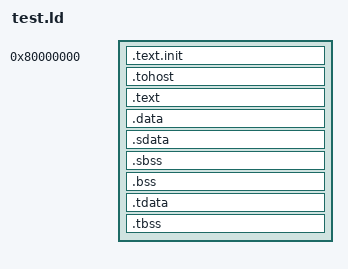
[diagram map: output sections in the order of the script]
/*======================================================================*/
/* Proxy kernel linker script                                           */
/*======================================================================*/
/* This is the linker script used to build the baremetal benchmarks     *
 * Compared to the original linker script shipped with riscv_tests this *
 * script has an aligned data section useful to run benchmarks on ISSes */

/*----------------------------------------------------------------------*/
/* Setup                                                                */
/*----------------------------------------------------------------------*/

/* The OUTPUT_ARCH command specifies the machine architecture where the
   argument is one of the names used in the BFD library. More
   specifically one of the entires in bfd/cpu-mips.c */

OUTPUT_ARCH( "riscv" )
ENTRY(_start)

/*----------------------------------------------------------------------*/
/* Sections                                                             */
/*----------------------------------------------------------------------*/

PHDRS
{
	text PT_LOAD FLAGS(SHF_ALLOC | SHF_EXECINSTR);
}

SECTIONS
{

  /* text: test code section */
  . = 0x80000000;
  .text.init : { *(.text.init) } : text

  . = ALIGN(0x1000);
  .tohost : { *(.tohost) }

  . = ALIGN(0x1000);
  .text : { *(.text) } : text

  /* This MUST be aligned, otherwise simulators that
     check for self-modifying code with page checks
     will be detecting smc with writes to the data segment */
  . = ALIGN(0x1000);
  .data : { *(.data) }

  .sdata : {
    __global_pointer$ = . + 0x800;
    *(.srodata.cst16) *(.srodata.cst8) *(.srodata.cst4) *(.srodata.cst2) *(.srodata*)
    *(.sdata .sdata.* .gnu.linkonce.s.*)
  }

  /* bss segment */
  .sbss : {
    *(.sbss .sbss.* .gnu.linkonce.sb.*)
    *(.scommon)
  }
  .bss : { *(.bss) }

  /* thread-local data segment */
  .tdata :
  {
    _tdata_begin = .;
    *(.tdata)
    _tdata_end = .;
  }
  .tbss :
  {
    *(.tbss)
    _tbss_end = .;
  }

  /* End of uninitalized data segement */
  _end = .;
}

